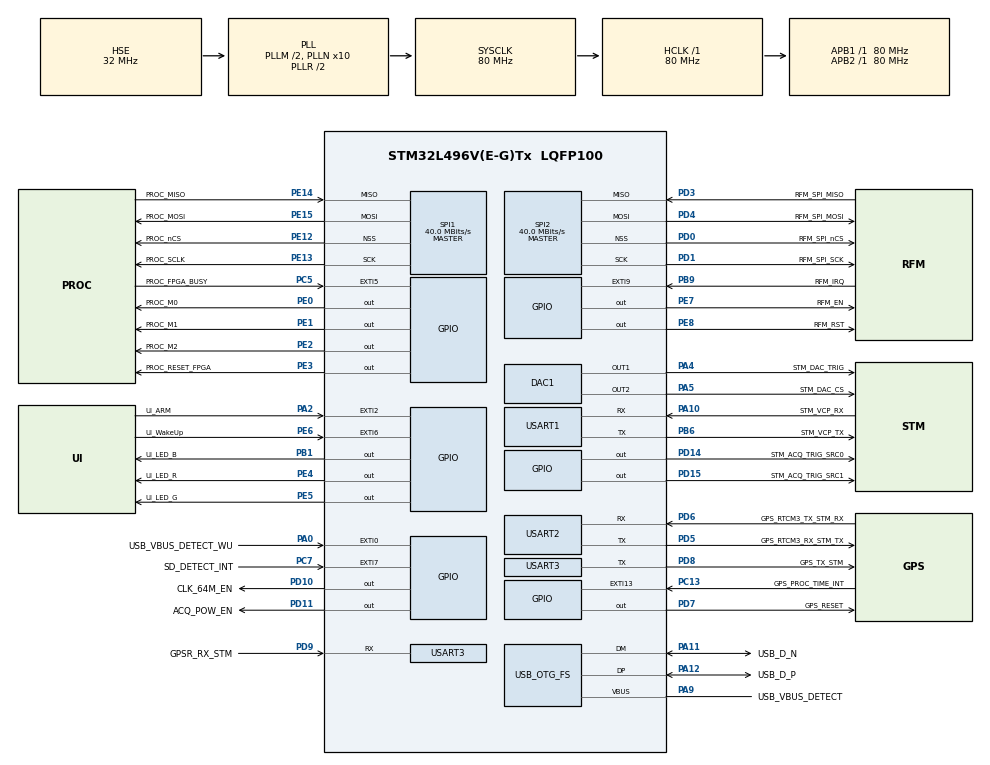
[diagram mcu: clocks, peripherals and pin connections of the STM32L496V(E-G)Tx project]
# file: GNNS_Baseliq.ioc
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DAC1.DAC_Channel-DAC_OUT2=DAC_CHANNEL_2
Mcu.Family=STM32L4
Mcu.Name=STM32L496V(E-G)Tx
Mcu.Package=LQFP100
NVIC.PriorityGroup=NVIC_PRIORITYGROUP_4
NVIC.USART1_IRQn=true\:0\:0\:false\:false\:true\:true\:true\:true
NVIC.USART2_IRQn=true\:0\:0\:false\:false\:true\:true\:true\:true
NVIC.USART3_IRQn=true\:0\:0\:false\:false\:true\:true\:true\:true
PA0.GPIO_Label=USB_VBUS_DETECT_WU
PA0.Signal=GPXTI0
PA10.GPIO_Label=STM_VCP_RX
PA10.Mode=Asynchronous
PA10.Signal=USART1_RX
PA11.GPIO_Label=USB_D_N
PA11.Mode=Device_Only
PA11.Signal=USB_OTG_FS_DM
PA12.GPIO_Label=USB_D_P
PA12.Mode=Device_Only
PA12.Signal=USB_OTG_FS_DP
PA13\ (JTMS/SWDIO).GPIO_Label=STM_SWDIO
PA13\ (JTMS/SWDIO).Mode=Trace_Asynchronous_SW
PA13\ (JTMS/SWDIO).Signal=SYS_JTMS-SWDIO
PA14\ (JTCK/SWCLK).GPIO_Label=STM_SWCLK
PA14\ (JTCK/SWCLK).Mode=Trace_Asynchronous_SW
PA14\ (JTCK/SWCLK).Signal=SYS_JTCK-SWCLK
PA2.GPIO_Label=UI_ARM
PA2.Signal=GPXTI2
PA4.GPIO_Label=STM_DAC_TRIG
PA4.Signal=COMP_DAC11_group
PA5.GPIO_Label=STM_DAC_CS
PA5.Signal=COMP_DAC12_group
PA9.GPIO_Label=USB_VBUS_DETECT
PA9.Mode=Activate_VBUS
PA9.Signal=USB_OTG_FS_VBUS
PB1.GPIO_Label=UI_LED_B
PB1.Signal=GPIO_Output
PB3\ (JTDO/TRACESWO).GPIO_Label=STM_SWO
PB3\ (JTDO/TRACESWO).Mode=Trace_Asynchronous_SW
PB3\ (JTDO/TRACESWO).Signal=SYS_JTDO-SWO
PB6.GPIO_Label=STM_VCP_TX
PB6.Mode=Asynchronous
PB6.Signal=USART1_TX
PB9.GPIO_Label=RFM_IRQ
PB9.Signal=GPXTI9
PC13.GPIO_Label=GPS_PROC_TIME_INT
PC13.Signal=GPXTI13
PC14-OSC32_IN\ (PC14).GPIO_Label=OSC_RTC_IN
PC14-OSC32_IN\ (PC14).Mode=LSE-External-Oscillator
PC14-OSC32_IN\ (PC14).Signal=RCC_OSC32_IN
PC15-OSC32_OUT\ (PC15).GPIO_Label=OSC_RTC_OUT
PC15-OSC32_OUT\ (PC15).Mode=LSE-External-Oscillator
PC15-OSC32_OUT\ (PC15).Signal=RCC_OSC32_OUT
PC5.GPIO_Label=PROC_FPGA_BUSY
PC5.Signal=GPXTI5
PC7.GPIO_Label=SD_DETECT_INT
PC7.Signal=GPXTI7
PD0.GPIO_Label=RFM_SPI_nCS
PD0.Mode=NSS_Signal_Hard_Output
PD0.Signal=SPI2_NSS
PD1.GPIO_Label=RFM_SPI_SCK
PD1.Mode=Full_Duplex_Master
PD1.Signal=SPI2_SCK
PD10.GPIO_Label=CLK_64M_EN
PD10.Signal=GPIO_Output
PD11.GPIO_Label=ACQ_POW_EN
PD11.PinState=GPIO_PIN_SET
PD11.Signal=GPIO_Output
PD14.GPIO_Label=STM_ACQ_TRIG_SRC0
PD14.Signal=GPIO_Output
PD15.GPIO_Label=STM_ACQ_TRIG_SRC1
PD15.Signal=GPIO_Output
PD3.GPIO_Label=RFM_SPI_MISO
PD3.Mode=Full_Duplex_Master
PD3.Signal=SPI2_MISO
PD4.GPIO_Label=RFM_SPI_MOSI
PD4.Mode=Full_Duplex_Master
PD4.Signal=SPI2_MOSI
PD5.GPIO_Label=GPS_RTCM3_RX_STM_TX
PD5.Mode=Asynchronous
PD5.Signal=USART2_TX
PD6.GPIO_Label=GPS_RTCM3_TX_STM_RX
PD6.Mode=Asynchronous
PD6.Signal=USART2_RX
PD7.GPIO_Label=GPS_RESET
PD7.PinState=GPIO_PIN_SET
PD7.Signal=GPIO_Output
PD8.GPIO_Label=GPS_TX_STM
PD8.GPIO_ModeDefaultPP=GPIO_MODE_AF_PP
PD8.GPIO_PuPd=GPIO_NOPULL
PD8.Mode=Asynchronous
PD8.Signal=USART3_TX
PD9.GPIO_Label=GPSR_RX_STM
PD9.Mode=Asynchronous
PD9.Signal=USART3_RX
PE0.GPIO_Label=PROC_M0
PE0.Signal=GPIO_Output
PE1.GPIO_Label=PROC_M1
PE1.Signal=GPIO_Output
PE12.GPIO_Label=PROC_nCS
PE12.Mode=NSS_Signal_Hard_Output
PE12.Signal=SPI1_NSS
PE13.GPIO_Label=PROC_SCLK
PE13.Mode=Full_Duplex_Master
PE13.Signal=SPI1_SCK
PE14.GPIO_Label=PROC_MISO
PE14.Mode=Full_Duplex_Master
PE14.Signal=SPI1_MISO
PE15.GPIO_Label=PROC_MOSI
PE15.Mode=Full_Duplex_Master
PE15.Signal=SPI1_MOSI
PE2.GPIO_Label=PROC_M2
PE2.Signal=GPIO_Output
PE3.GPIO_Label=PROC_RESET_FPGA
PE3.Signal=GPIO_Output
PE4.GPIO_Label=UI_LED_R
PE4.PinState=GPIO_PIN_RESET
PE4.Signal=GPIO_Output
PE5.GPIO_Label=UI_LED_G
PE5.Signal=GPIO_Output
PE6.GPIO_Label=UI_WakeUp
PE6.Signal=GPXTI6
PE7.GPIO_Label=RFM_EN
PE7.Signal=GPIO_Output
PE8.GPIO_Label=RFM_RST
PE8.Signal=GPIO_Output
PH0-OSC_IN\ (PH0).GPIO_Label=OSC_IN
PH0-OSC_IN\ (PH0).Mode=HSE-External-Oscillator
PH0-OSC_IN\ (PH0).Signal=RCC_OSC_IN
PH1-OSC_OUT\ (PH1).GPIO_Label=OSC_OUT
PH1-OSC_OUT\ (PH1).Mode=HSE-External-Oscillator
PH1-OSC_OUT\ (PH1).Signal=RCC_OSC_OUT
ProjectManager.HeapSize=0x200
ProjectManager.StackSize=0x400
ProjectManager.TargetToolchain=STM32CubeIDE
RCC.ADCFreq_Value=96000000
RCC.AHBFreq_Value=80000000
RCC.APB1Freq_Value=80000000
RCC.APB1TimFreq_Value=80000000
RCC.APB2Freq_Value=80000000
RCC.APB2TimFreq_Value=80000000
RCC.CortexFreq_Value=80000000
RCC.HCLKFreq_Value=80000000
RCC.HSE_VALUE=32000000
RCC.HSI48_VALUE=48000000
RCC.HSI_VALUE=16000000
RCC.MSI_VALUE=4000000
RCC.PLLM=2
RCC.PLLN=10
RCC.PLLSAI1N=12
RCC.PLLSAI1Q=RCC_PLLQ_DIV4
RCC.PLLSourceVirtual=RCC_PLLSOURCE_HSE
RCC.SYSCLKFreq_VALUE=80000000
RCC.SYSCLKSource=RCC_SYSCLKSOURCE_PLLCLK
RCC.USBFreq_Value=48000000
RCC.VCOOutputFreq_Value=160000000
SH.COMP_DAC11_group.0=DAC1_OUT1,DAC_OUT1
SH.COMP_DAC12_group.0=DAC1_OUT2,DAC_OUT2
SPI1.BaudRatePrescaler=SPI_BAUDRATEPRESCALER_2
SPI1.CalculateBaudRate=40.0 MBits/s
SPI1.Direction=SPI_DIRECTION_2LINES
SPI1.Mode=SPI_MODE_MASTER
SPI1.VirtualNSS=VM_NSSHARD
SPI1.VirtualType=VM_MASTER
SPI2.BaudRatePrescaler=SPI_BAUDRATEPRESCALER_2
SPI2.CalculateBaudRate=40.0 MBits/s
SPI2.Direction=SPI_DIRECTION_2LINES
SPI2.Mode=SPI_MODE_MASTER
SPI2.VirtualNSS=VM_NSSHARD
SPI2.VirtualType=VM_MASTER
USART1.SwapParam=ADVFEATURE_SWAP_ENABLE
USART1.VirtualMode-Asynchronous=VM_ASYNC
USART2.VirtualMode-Asynchronous=VM_ASYNC
USART3.BaudRate=38400
USART3.DataInvertParam=ADVFEATURE_DATAINV_DISABLE
USART3.TxPinLevelInvertParam=ADVFEATURE_TXINV_DISABLE
USART3.VirtualMode-Asynchronous=VM_ASYNC
USB_OTG_FS.VirtualMode=Device_Only
board=custom

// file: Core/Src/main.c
/* USER CODE BEGIN Header */
/**
 ******************************************************************************
 * @file           : main.c
 * @brief          : Main program body
 ******************************************************************************
 * @attention
 *
 * Copyright (c) 2024 STMicroelectronics.
 * All rights reserved.
 *
 * This software is licensed under terms that can be found in the LICENSE file
 * in the root directory of this software component.
 * If no LICENSE file comes with this software, it is provided AS-IS.
 *
 ******************************************************************************
 */
/* USER CODE END Header */
#include "main.h"
#include "dac.h"
#include "spi.h"
#include "usart.h"
#include "usb_otg.h"
#include "gpio.h"

void SystemClock_Config(void);

int main(void)
{

  /* MCU Configuration--------------------------------------------------------*/

  /* Reset of all peripherals, Initializes the Flash interface and the Systick. */
	HAL_Init();

  /* Configure the system clock */
  SystemClock_Config();

  /* Initialize all configured peripherals */
  MX_GPIO_Init();
  MX_DAC1_Init();
  MX_SPI1_Init();
  MX_SPI2_Init();
  MX_USART1_UART_Init();
  MX_USART2_UART_Init();
  MX_USB_OTG_FS_PCD_Init();
  MX_USART3_UART_Init();
  /* USER CODE BEGIN 2 */
	HAL_GPIO_WritePin(GPIOE, GPIO_PIN_4,GPIO_PIN_SET);

	const char startMessage[] = "\r\nStarting...\r\n";
	const char initDoneMessage[] = "\r\nInit Done\r\n\n";

	HAL_UART_Transmit(&huart1, (uint8_t *)startMessage, sizeof(startMessage), 10);
	GNSSCom_Init(&huart3,&huart1);
	HAL_UART_Transmit(&huart1, (uint8_t *)initDoneMessage, sizeof(initDoneMessage), 10);

	HAL_GPIO_TogglePin(GPIOE, GPIO_PIN_4);HAL_GPIO_TogglePin(GPIOE, GPIO_PIN_5);
	HAL_Delay(1000);

  /* USER CODE END 2 */

  /* Infinite loop */
	while (1)
	{

	}
}

void SystemClock_Config(void)
{
  RCC_OscInitTypeDef RCC_OscInitStruct = {0};
  RCC_ClkInitTypeDef RCC_ClkInitStruct = {0};

  /** Configure the main internal regulator output voltage
  */
  if (HAL_PWREx_ControlVoltageScaling(PWR_REGULATOR_VOLTAGE_SCALE1) != HAL_OK)
  {
    Error_Handler();
  }

  /** Initializes the RCC Oscillators according to the specified parameters
  * in the RCC_OscInitTypeDef structure.
  */
  RCC_OscInitStruct.OscillatorType = RCC_OSCILLATORTYPE_HSE;
  RCC_OscInitStruct.HSEState = RCC_HSE_ON;
  RCC_OscInitStruct.PLL.PLLState = RCC_PLL_ON;
  RCC_OscInitStruct.PLL.PLLSource = RCC_PLLSOURCE_HSE;
  RCC_OscInitStruct.PLL.PLLM = 2;
  RCC_OscInitStruct.PLL.PLLN = 10;
  RCC_OscInitStruct.PLL.PLLP = RCC_PLLP_DIV2;
  RCC_OscInitStruct.PLL.PLLQ = RCC_PLLQ_DIV2;
  RCC_OscInitStruct.PLL.PLLR = RCC_PLLR_DIV2;
  if (HAL_RCC_OscConfig(&RCC_OscInitStruct) != HAL_OK)
  {
    Error_Handler();
  }

  /** Initializes the CPU, AHB and APB buses clocks
  */
  RCC_ClkInitStruct.ClockType = RCC_CLOCKTYPE_HCLK|RCC_CLOCKTYPE_SYSCLK
                              |RCC_CLOCKTYPE_PCLK1|RCC_CLOCKTYPE_PCLK2;
  RCC_ClkInitStruct.SYSCLKSource = RCC_SYSCLKSOURCE_PLLCLK;
  RCC_ClkInitStruct.AHBCLKDivider = RCC_SYSCLK_DIV1;
  RCC_ClkInitStruct.APB1CLKDivider = RCC_HCLK_DIV1;
  RCC_ClkInitStruct.APB2CLKDivider = RCC_HCLK_DIV1;

  if (HAL_RCC_ClockConfig(&RCC_ClkInitStruct, FLASH_LATENCY_4) != HAL_OK)
  {
    Error_Handler();
  }
}

void Error_Handler(void)
{
	__disable_irq();
	while (1)
	{
	}
}
